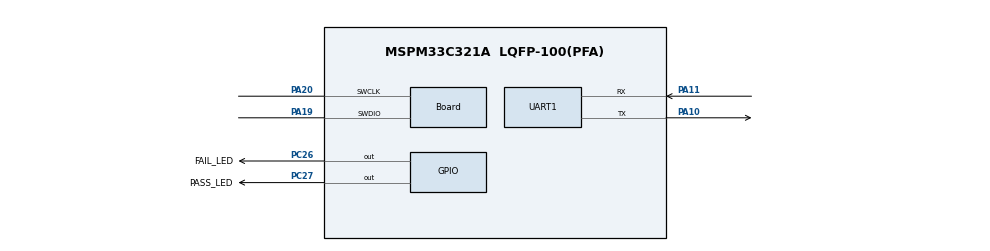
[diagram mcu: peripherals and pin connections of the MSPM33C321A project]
//@cliArgs --device "MSPM33C321A" --package "LQFP-100(PFA)" --part "Default"
//@v2CliArgs --device "MSPM33C321A" --package "LQFP-100(PFA)"
// @cliArgs --board /ti/boards/LP_MSPM33C321A --rtos nortos


/**
 * Import the modules used in this configuration.
 */
const GPIO   = scripting.addModule("/ti/driverlib/GPIO", {}, false);
const GPIO1  = GPIO.addInstance();
const SYSCTL = scripting.addModule("/ti/driverlib/SYSCTL");
const UART   = scripting.addModule("/ti/driverlib/UART", {}, false);
const UART1  = UART.addInstance();


/**
 * Write custom configuration values to the imported modules.
 */
GPIO1.$name                                 = "GPIO_LEDS";
GPIO1.associatedPins.create(2);
GPIO1.associatedPins[0].$name               = "FAIL_LED";
GPIO1.associatedPins[0].assignedPort        = "PORTC";
GPIO1.associatedPins[0].assignedPortSegment = "Upper";
GPIO1.associatedPins[0].assignedPin         = "26";
GPIO1.associatedPins[0].launchPadShortcut   = "LED2RedEn";
GPIO1.associatedPins[0].pin.$assign         = "PC26";
GPIO1.associatedPins[1].$name               = "PASS_LED";
GPIO1.associatedPins[1].launchPadShortcut   = "LED2GreenEn";
GPIO1.associatedPins[1].pin.$assign         = "PC27";

const Board                       = scripting.addModule("/ti/driverlib/Board", {}, false);
Board.peripheral.$assign          = "DEBUGSS";
Board.peripheral.swclkPin.$assign = "PA20";
Board.peripheral.swdioPin.$assign = "PA19";

SYSCTL.forceDefaultClkConfig = true;
SYSCTL.peripheral.$assign    = "SYSCTL";

UART1.$name                    = "UART_0";
UART1.targetBaudRate           = 115200;
UART1.enableFIFO               = true;
UART1.rxFifoThreshold          = "DL_UART_RX_FIFO_LEVEL_ONE_ENTRY";
UART1.enableInternalLoopback   = true;
UART1.enableDMARX              = false;
UART1.enableDMATX              = false;
UART1.txFifoThreshold          = "DL_UART_TX_FIFO_LEVEL_EMPTY";
UART1.peripheral.$assign       = "UC12";
UART1.peripheral.rxPin.$assign = "PA11";
UART1.peripheral.txPin.$assign = "PA10";
UART1.txPinConfig.$name        = "ti_driverlib_gpio_GPIOPinGeneric0";
UART1.txPinConfig.enableConfig = true;
UART1.rxPinConfig.$name        = "ti_driverlib_gpio_GPIOPinGeneric1";
UART1.rxPinConfig.enableConfig = true;

const ProjectConfig              = scripting.addModule("/ti/project_config/ProjectConfig", {}, false);
ProjectConfig.migrationCondition = true;

ProjectConfig.genLinker  = true;
ProjectConfig.genStartup = true;
ProjectConfig.genOpts    = true;
ProjectConfig.genLibs    = true;
